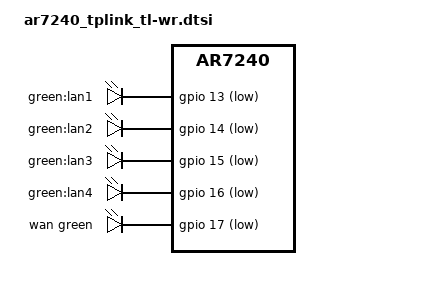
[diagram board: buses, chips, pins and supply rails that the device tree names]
// SPDX-License-Identifier: GPL-2.0-or-later OR MIT

#include <dt-bindings/leds/common.h>

#include "ar7240_tplink.dtsi"

&leds {
	lan1 {
		label = "green:lan1";
		gpios = <&gpio 13 GPIO_ACTIVE_LOW>;
	};

	lan2 {
		label = "green:lan2";
		gpios = <&gpio 14 GPIO_ACTIVE_LOW>;
	};

	lan3 {
		label = "green:lan3";
		gpios = <&gpio 15 GPIO_ACTIVE_LOW>;
	};

	lan4 {
		label = "green:lan4";
		gpios = <&gpio 16 GPIO_ACTIVE_LOW>;
	};

	wan {
		function = LED_FUNCTION_WAN;
		color = <LED_COLOR_ID_GREEN>;
		gpios = <&gpio 17 GPIO_ACTIVE_LOW>;
	};
};

&eth0 {
	nvmem-cells = <&macaddr_uboot_1fc00 (-1)>;
	nvmem-cell-names = "mac-address";
};

&eth1 {
	nvmem-cells = <&macaddr_uboot_1fc00 1>;
	nvmem-cell-names = "mac-address";
};

&ath9k {
	compatible = "pci168c,002b";
};
